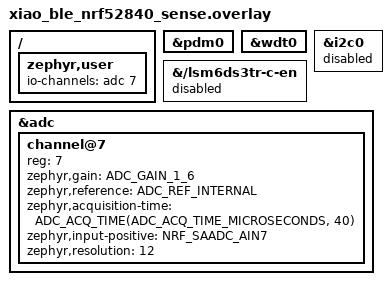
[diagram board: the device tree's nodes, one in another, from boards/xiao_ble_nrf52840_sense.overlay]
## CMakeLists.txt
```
cmake_minimum_required(VERSION 3.20.0)
find_package(Zephyr REQUIRED HINTS $ENV{ZEPHYR_BASE})
project(keepsake_p0)

target_sources(app PRIVATE src/main.c)

# Backport Zephyr 8260e1ff5cc4 (DMA slab ownership). Generate into the build
# directory: never modify the west checkout or depend on an untracked edit.
set(pdm_original ${ZEPHYR_BASE}/drivers/audio/dmic_nrfx_pdm.c)
set(pdm_patch ${CMAKE_CURRENT_SOURCE_DIR}/../patches/zephyr-pdm-ownership.patch)
file(SHA256 ${pdm_original} pdm_sha)
if(NOT pdm_sha STREQUAL "60f8dd2504aa72fa922262f3206bf8f4934a6689186cfa0d31728e76f8ca50df")
  message(FATAL_ERROR "PDM source changed: review/remove the v4.1.0 ownership backport")
endif()
set_property(DIRECTORY APPEND PROPERTY CMAKE_CONFIGURE_DEPENDS ${pdm_patch} ${pdm_original})
find_program(PATCH_EXECUTABLE patch REQUIRED)
set(pdm_fixed ${CMAKE_CURRENT_BINARY_DIR}/dmic_nrfx_pdm_fixed.c)
file(REMOVE ${pdm_fixed})
execute_process(COMMAND ${PATCH_EXECUTABLE} -s -o ${pdm_fixed} ${pdm_original} ${pdm_patch}
                RESULT_VARIABLE patch_result)
if(NOT patch_result EQUAL 0)
  message(FATAL_ERROR "Cannot apply PDM ownership backport")
endif()
get_target_property(audio_sources drivers__audio SOURCES)
list(FILTER audio_sources EXCLUDE REGEX "(^|/)dmic_nrfx_pdm\\.c$")
set_property(TARGET drivers__audio PROPERTY SOURCES ${audio_sources})
target_sources(drivers__audio PRIVATE ${pdm_fixed})
```

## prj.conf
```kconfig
# Native PCM16/16 kHz. No audio DSP or codec.
CONFIG_AUDIO=y
CONFIG_AUDIO_DMIC=y
CONFIG_ADC=y
CONFIG_BT=y
CONFIG_BT_PERIPHERAL=y
CONFIG_BT_MAX_CONN=1
CONFIG_BT_DEVICE_NAME="Keepsake-P0"
CONFIG_BT_SMP=n
CONFIG_BT_CTLR_PHY_2M=y
CONFIG_BT_AUTO_PHY_UPDATE=y
CONFIG_BT_USER_PHY_UPDATE=y
CONFIG_BT_AUTO_DATA_LEN_UPDATE=y
CONFIG_BT_USER_DATA_LEN_UPDATE=y
CONFIG_BT_DATA_LEN_UPDATE=y
CONFIG_BT_CTLR_DATA_LENGTH_MAX=251
CONFIG_BT_L2CAP_TX_MTU=247
CONFIG_BT_BUF_ACL_TX_SIZE=251
CONFIG_BT_BUF_ACL_RX_SIZE=251
# Match controller-facing buffers to upper-layer TX capacity (previous default: 3).
CONFIG_BT_BUF_ACL_TX_COUNT=16
CONFIG_BT_BUF_EVT_RX_COUNT=20
CONFIG_BT_CONN_TX_MAX=16
CONFIG_BT_L2CAP_TX_BUF_COUNT=16
CONFIG_BT_ATT_PREPARE_COUNT=0
CONFIG_WATCHDOG=y
CONFIG_REBOOT=y
CONFIG_MAIN_STACK_SIZE=4096
CONFIG_SYSTEM_WORKQUEUE_STACK_SIZE=2048
# No idle UART clock/logging overhead; optional debug.conf restores serial output.
CONFIG_SERIAL=n
CONFIG_CONSOLE=n
CONFIG_UART_CONSOLE=n
CONFIG_PRINTK=n
CONFIG_LOG=n
CONFIG_BOOT_BANNER=n
CONFIG_USB_DEVICE_STACK=n
```

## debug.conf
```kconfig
CONFIG_SERIAL=y
CONFIG_CONSOLE=y
CONFIG_UART_CONSOLE=y
CONFIG_PRINTK=y
CONFIG_LOG=y
CONFIG_LOG_DEFAULT_LEVEL=3
CONFIG_BOOT_BANNER=y
CONFIG_USB_DEVICE_STACK=y
```

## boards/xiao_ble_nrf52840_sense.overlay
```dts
&pdm0 { status = "okay"; };
&wdt0 { status = "okay"; };
/* Unused IMU must not be powered by the board's boot-on fixed regulator. */
&{/lsm6ds3tr-c-en} { status = "disabled"; };
&i2c0 { status = "disabled"; };
/ {
    zephyr,user {
        io-channels = <&adc 7>;
    };
};
&adc {
    status = "okay";
    #address-cells = <1>;
    #size-cells = <0>;
    channel@7 {
        reg = <7>;
        zephyr,gain = "ADC_GAIN_1_6";
        zephyr,reference = "ADC_REF_INTERNAL";
        zephyr,acquisition-time = <ADC_ACQ_TIME(ADC_ACQ_TIME_MICROSECONDS, 40)>;
        zephyr,input-positive = <NRF_SAADC_AIN7>;
        zephyr,resolution = <12>;
    };
};
/* The board already configures reg1 for DC/DC. No raw register override needed. */
```

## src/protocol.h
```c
#ifndef KEEPSAKE_PROTOCOL_H
#define KEEPSAKE_PROTOCOL_H
#include <stdint.h>
#include <stddef.h>
#include <string.h>
#define KS_RATE 16000U
#define KS_BLOCK_MS 100U
#define KS_BLOCK_BYTES (KS_RATE * KS_BLOCK_MS / 1000U * 2U)
#define KS_HEADER_BYTES 5U
#define KS_MAX_PAYLOAD 232U
#define KS_INFO_BYTES 20U
static inline void ks_put32(uint32_t value, uint8_t *out)
{
    for (unsigned i = 0; i < 4; ++i) { out[i] = (uint8_t)(value >> (8U * i)); }
}
static inline size_t ks_payload(uint16_t mtu)
{
    if (mtu <= 3U + KS_HEADER_BYTES + 1U) { return 0; }
    size_t bytes = mtu - 3U - KS_HEADER_BYTES;
    if (bytes > KS_MAX_PAYLOAD) { bytes = KS_MAX_PAYLOAD; }
    return bytes & ~(size_t)1; /* Complete PCM16 samples, without changing samples. */
}
static inline uint32_t ks_packet_count(size_t bytes, size_t payload)
{
    return payload ? (uint32_t)((bytes + payload - 1U) / payload) : 0;
}
/* Read-only descriptor; fits a default ATT read (22 bytes). */
static inline void ks_stream_info(uint8_t out[KS_INFO_BYTES], uint32_t boot_id)
{
    memcpy(out, "KSR1", 4);
    ks_put32(KS_RATE, out + 4);
    out[8] = KS_BLOCK_MS; out[9] = 0;
    out[10] = 1; out[11] = 16; out[12] = KS_HEADER_BYTES;
    out[13] = 1; /* bit 0: no software audio processing */
    out[14] = 0; /* hardware gain in dB */
    out[15] = 0;
    ks_put32(boot_id, out + 16);
}
#endif
```

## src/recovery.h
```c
#ifndef KEEPSAKE_RECOVERY_H
#define KEEPSAKE_RECOVERY_H
#include <stdbool.h>
#include <stdint.h>

enum ks_recovery_action { KS_RECOVERY_NONE, KS_RECOVERY_TX, KS_RECOVERY_SUPERVISOR };

/* Called frequently; these deadlines are well below half the 32-bit clock
 * range. A concurrent timestamp newer than 'now' is fresh, not overdue.
 */
static inline enum ks_recovery_action ks_recovery_due(uint32_t now,
    uint32_t last_supervision, uint32_t last_tx, bool streaming)
{
    if ((int32_t)(now - last_supervision) > 20000) { return KS_RECOVERY_SUPERVISOR; }
    if (streaming && (int32_t)(now - last_tx) > 15000) { return KS_RECOVERY_TX; }
    return KS_RECOVERY_NONE;
}
#endif
```
